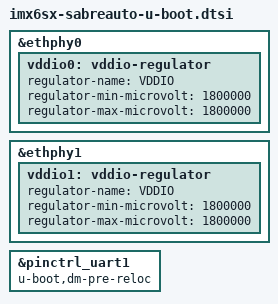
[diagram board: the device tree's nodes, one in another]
// SPDX-License-Identifier: GPL-2.0+
/*
 * Copyright 2018 NXP
 */

&ethphy0 {
	vddio0: vddio-regulator {
		regulator-name = "VDDIO";
		regulator-min-microvolt = <1800000>;
		regulator-max-microvolt = <1800000>;
	};
};

&ethphy1 {
	vddio1: vddio-regulator {
		regulator-name = "VDDIO";
		regulator-min-microvolt = <1800000>;
		regulator-max-microvolt = <1800000>;
	};
};

&pinctrl_uart1 {
	u-boot,dm-pre-reloc;
};
